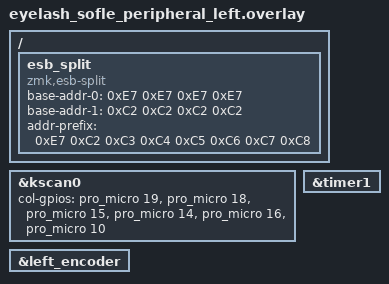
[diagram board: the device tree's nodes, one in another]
/*
*
* Copyright (c) 2021 Darryl deHaan
* SPDX-License-Identifier: MIT
*
*/

#include "eyelash_sofle.dtsi"

&kscan0 {
    col-gpios
        = <&pro_micro 19 GPIO_ACTIVE_HIGH>
        , <&pro_micro 18 GPIO_ACTIVE_HIGH>
        , <&pro_micro 15 GPIO_ACTIVE_HIGH>
        , <&pro_micro 14 GPIO_ACTIVE_HIGH>
        , <&pro_micro 16 GPIO_ACTIVE_HIGH>
        , <&pro_micro 10 GPIO_ACTIVE_HIGH>
        ;
};

&left_encoder {
    status = "okay";
};

&timer1 {
    status = "okay";
};

/{
    esb_split {
        compatible = "zmk,esb-split";
        // These are arbitrary default addresses. In end user products
        // different addresses should be used for each set of devices.
        base-addr-0 = <0xE7 0xE7 0xE7 0xE7>;
        base-addr-1 = <0xC2 0xC2 0xC2 0xC2>;
        addr-prefix = <0xE7 0xC2 0xC3 0xC4 0xC5 0xC6 0xC7 0xC8>;
    };
};
